# STM32U5Gx register map
File version: 1.0
CPU: CM33 r0p1, little endian, MPU, FPU, 4 interrupt priority bits
Registers are 32-bit, read-write, reset 0x0 unless marked. A register's access mark holds for its fields unless they carry their own. Offsets are from the block's base; [hi:lo] are bit positions; {n}, {i} and the like mark numbered series.

## DCMI — Digital camera interface
Base 0x4202C000
Same registers: SEC_DCMI 0x5202C000
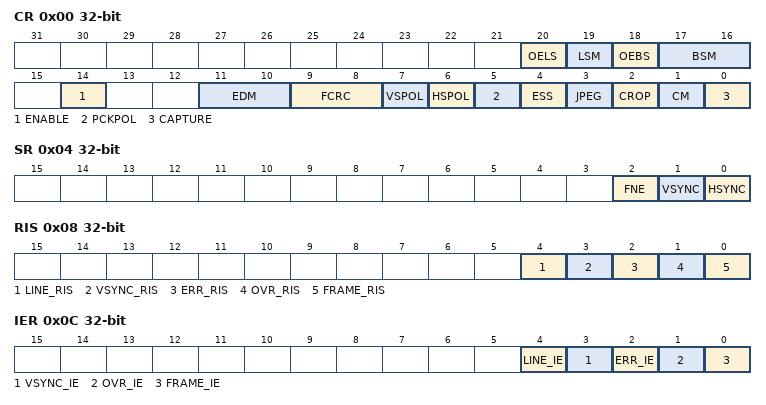
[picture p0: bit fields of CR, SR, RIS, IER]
0x00 CR — control register
  [20] OELS — Odd/Even Line Select (Line Select Start)
  [19] LSM — Line Select mode
  [18] OEBS — Odd/Even Byte Select (Byte Select Start)
  [17:16] BSM — Byte Select mode
  [14] ENABLE — DCMI enable
  [11:10] EDM — Extended data mode
  [9:8] FCRC — Frame capture rate control
  [7] VSPOL — Vertical synchronization polarity
  [6] HSPOL — Horizontal synchronization polarity
  [5] PCKPOL — Pixel clock polarity
  [4] ESS — Embedded synchronization select
  [3] JPEG — JPEG format
  [2] CROP — Crop feature
  [1] CM — Capture mode
  [0] CAPTURE — Capture enable
0x04 SR ro — status register
  [2] FNE — FIFO not empty
  [1] VSYNC — Vertical synchronization
  [0] HSYNC — Horizontal synchronization
0x08 RIS ro — raw interrupt status register
  [4] LINE_RIS — Line raw interrupt status
  [3] VSYNC_RIS — DCMI_VSYNC raw interrupt status
  [2] ERR_RIS — Synchronization error raw interrupt status
  [1] OVR_RIS — Overrun raw interrupt status
  [0] FRAME_RIS — Capture complete raw interrupt status
0x0C IER — interrupt enable register
  [4] LINE_IE — Line interrupt enable
  [3] VSYNC_IE — DCMI_VSYNC interrupt enable
  [2] ERR_IE — Synchronization error interrupt enable
  [1] OVR_IE — Overrun interrupt enable
  [0] FRAME_IE — Capture complete interrupt enable
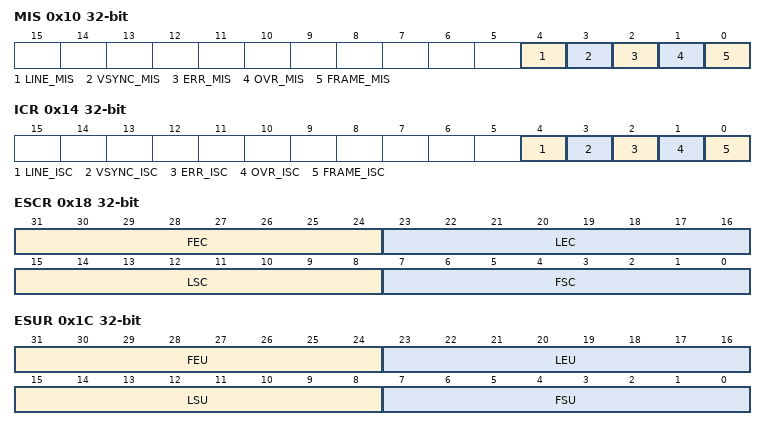
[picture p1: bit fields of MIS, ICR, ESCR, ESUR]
0x10 MIS ro — masked interrupt status register
  [4] LINE_MIS — Line masked interrupt status
  [3] VSYNC_MIS — VSYNC masked interrupt status
  [2] ERR_MIS — Synchronization error masked interrupt status
  [1] OVR_MIS — Overrun masked interrupt status
  [0] FRAME_MIS — Capture complete masked interrupt status
0x14 ICR wo — interrupt clear register
  [4] LINE_ISC — line interrupt status clear
  [3] VSYNC_ISC — Vertical Synchronization interrupt status clear
  [2] ERR_ISC — Synchronization error interrupt status clear
  [1] OVR_ISC — Overrun interrupt status clear
  [0] FRAME_ISC — Capture complete interrupt status clear
0x18 ESCR — background offset register
  [31:24] FEC — Frame end delimiter code
  [23:16] LEC — Line end delimiter code
  [15:8] LSC — Line start delimiter code
  [7:0] FSC — Frame start delimiter code
0x1C ESUR — embedded synchronization unmask register
  [31:24] FEU — Frame end delimiter unmask
  [23:16] LEU — Line end delimiter unmask
  [15:8] LSU — Line start delimiter unmask
  [7:0] FSU — Frame start delimiter unmask
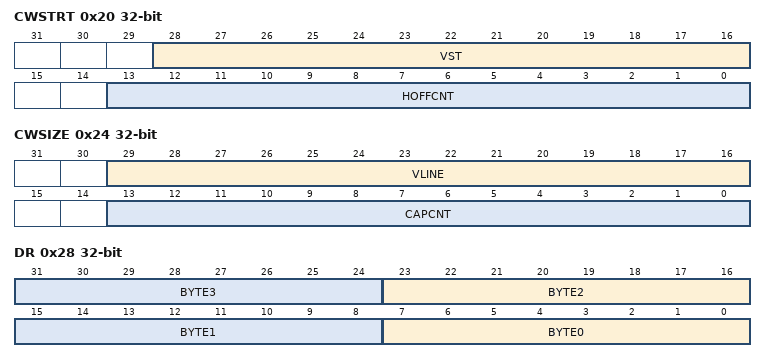
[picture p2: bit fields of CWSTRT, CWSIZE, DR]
0x20 CWSTRT — crop window start
  [28:16] VST — Vertical start line count
  [13:0] HOFFCNT — Horizontal offset count
0x24 CWSIZE — crop window size
  [29:16] VLINE — Vertical line count
  [13:0] CAPCNT — Capture count
0x28 DR ro — data register
  [8n+7:8n] BYTE{n} (n=0..3) — Data byte {n}

## DLYBOS1 — The delay block (DLYB) is used to generate an output clock that is dephased from the input clock
Base 0x420CF000
Same registers: DLYBSD1 0x420C8400, DLYBSD2 0x420C8800, DLYBOS2 0x420CF400, SEC_DLYBSD1 0x520C8400, SEC_DLYBSD2 0x520C8800, SEC_DLYBOS1 0x520CF000, SEC_DLYBOS2 0x520CF400
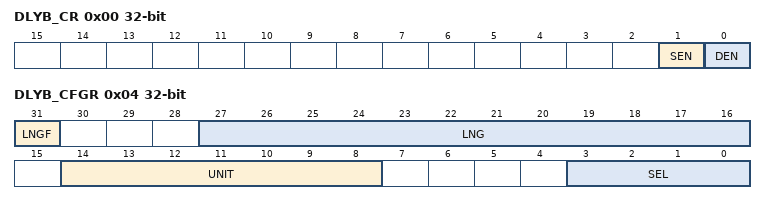
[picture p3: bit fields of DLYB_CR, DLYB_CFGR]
0x00 DLYB_CR — control register
  [1] SEN — OPALPM
  [0] DEN — Operational amplifier Enable
0x04 DLYB_CFGR access per field — configuration register
  [31] LNGF ro, [27:16] LNG ro, [14:8] UNIT rw, [3:0] SEL rw

## FMAC — Filter Math Accelerator
Base 0x40021400
Same registers: SEC_FMAC 0x50021400
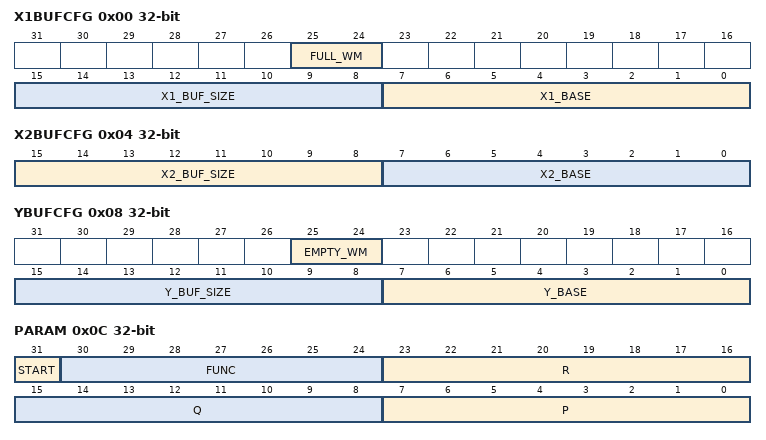
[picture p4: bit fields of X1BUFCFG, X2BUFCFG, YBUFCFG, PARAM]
0x00 X1BUFCFG — FMAC X1 Buffer Configuration register
  [25:24] FULL_WM — Watermark for buffer full flag
  [15:8] X1_BUF_SIZE — Allocated size of X1 buffer in 16-bit words
  [7:0] X1_BASE — Base address of X1 buffer
0x04 X2BUFCFG — FMAC X2 Buffer Configuration register
  [15:8] X2_BUF_SIZE — Size of X2 buffer in 16-bit words
  [7:0] X2_BASE — Base address of X2 buffer
0x08 YBUFCFG — FMAC Y Buffer Configuration register
  [25:24] EMPTY_WM — Watermark for buffer empty flag
  [15:8] Y_BUF_SIZE — Size of Y buffer in 16-bit words
  [7:0] Y_BASE — Base address of Y buffer
0x0C PARAM — FMAC Parameter register
  [31] START — Enable execution
  [30:24] FUNC — Function
  [23:16] R — Input parameter R
  [15:8] Q — Input parameter Q
  [7:0] P — Input parameter P
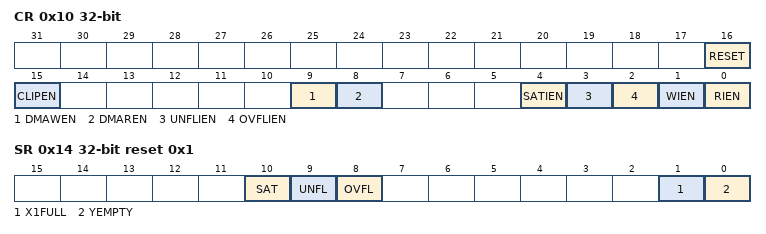
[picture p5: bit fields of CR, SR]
0x10 CR — FMAC Control register
  [16] RESET — Reset FMAC unit
  [15] CLIPEN — Enable clipping
  [9] DMAWEN — Enable DMA write channel requests
  [8] DMAREN — Enable DMA read channel requests
  [4] SATIEN — Enable saturation error interrupts
  [3] UNFLIEN — Enable underflow error interrupts
  [2] OVFLIEN — Enable overflow error interrupts
  [1] WIEN — Enable write interrupt
  [0] RIEN — Enable read interrupt
0x14 SR ro reset 0x1 — FMAC Status register
  [10] SAT — Saturation error flag
  [9] UNFL — Underflow error flag
  [8] OVFL — Overflow error flag
  [1] X1FULL — X1 buffer full flag
  [0] YEMPTY — Y buffer empty flag
0x18 WDATA wo — FMAC Write Data register
  [15:0] WDATA — Write data
0x1C RDATA ro — FMAC Read Data register
  [15:0] RDATA — Read data
